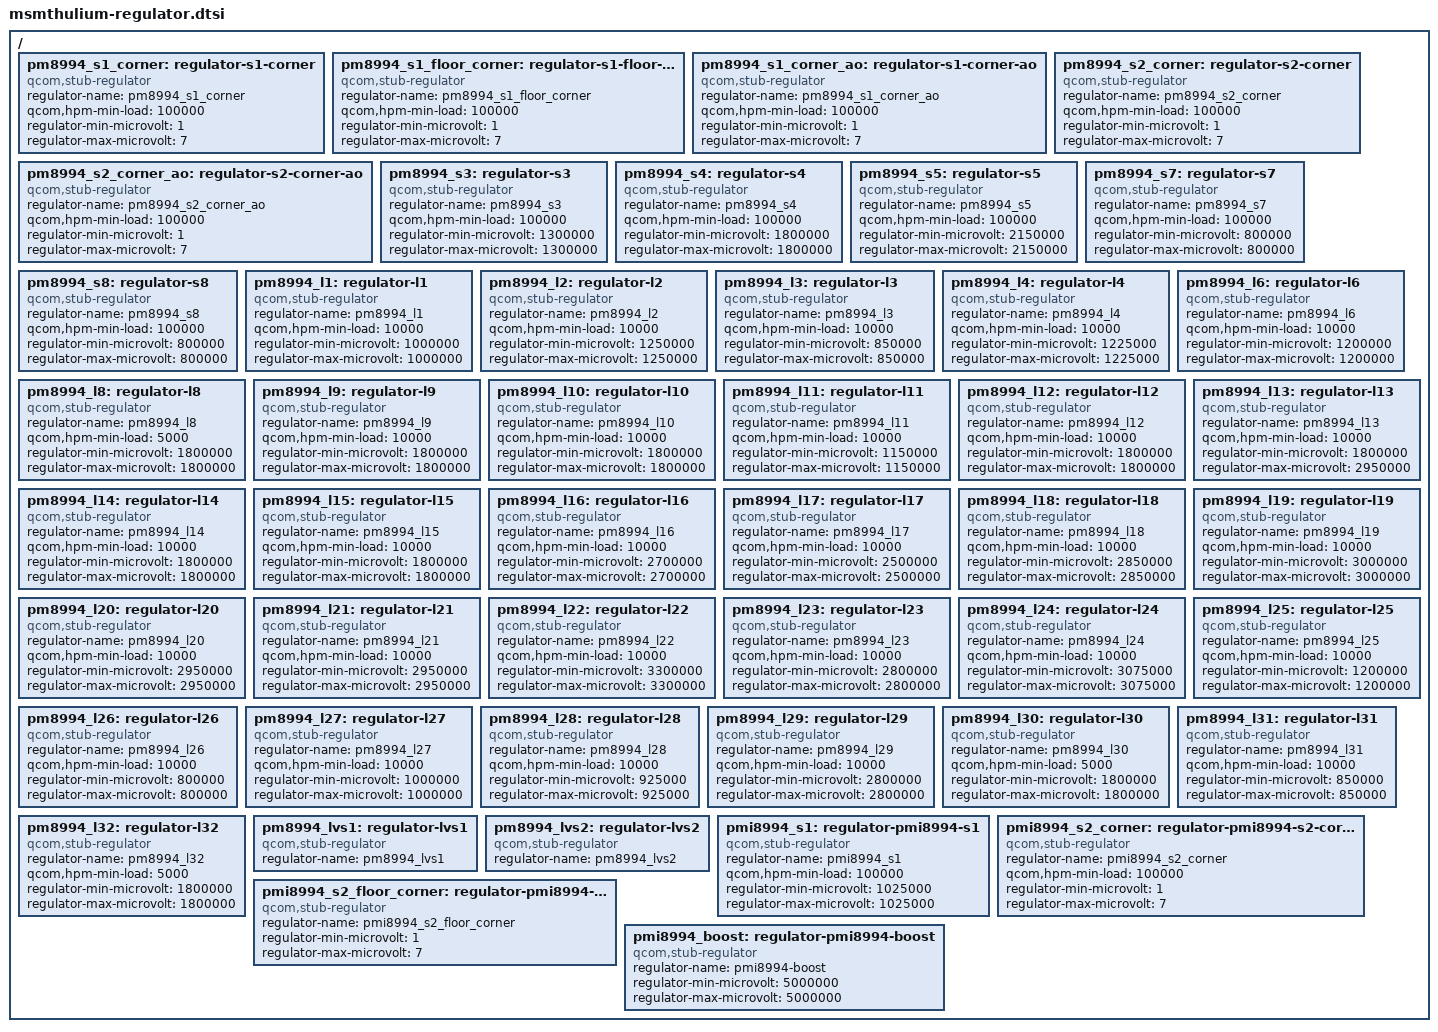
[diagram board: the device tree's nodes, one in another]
/* Copyright (c) 2014, The Linux Foundation. All rights reserved.
 *
 * This program is free software; you can redistribute it and/or modify
 * it under the terms of the GNU General Public License version 2 and
 * only version 2 as published by the Free Software Foundation.
 *
 * This program is distributed in the hope that it will be useful,
 * but WITHOUT ANY WARRANTY; without even the implied warranty of
 * MERCHANTABILITY or FITNESS FOR A PARTICULAR PURPOSE.  See the
 * GNU General Public License for more details.
 */

/* Stub regulators */

/ {
	/* PM8994 S1 + S6 = 2 phase VDD_CX supply */
	pm8994_s1_corner: regulator-s1-corner {
		compatible = "qcom,stub-regulator";
		regulator-name = "pm8994_s1_corner";
		qcom,hpm-min-load = <100000>;
		regulator-min-microvolt = <1>;
		regulator-max-microvolt = <7>;
	};

	pm8994_s1_floor_corner: regulator-s1-floor-corner {
		compatible = "qcom,stub-regulator";
		regulator-name = "pm8994_s1_floor_corner";
		qcom,hpm-min-load = <100000>;
		regulator-min-microvolt = <1>;
		regulator-max-microvolt = <7>;
	};

	pm8994_s1_corner_ao: regulator-s1-corner-ao {
		compatible = "qcom,stub-regulator";
		regulator-name = "pm8994_s1_corner_ao";
		qcom,hpm-min-load = <100000>;
		regulator-min-microvolt = <1>;
		regulator-max-microvolt = <7>;
	};

	/* PM8994 S2 + S12 = 2 phase VDD_MX supply */
	pm8994_s2_corner: regulator-s2-corner {
		compatible = "qcom,stub-regulator";
		regulator-name = "pm8994_s2_corner";
		qcom,hpm-min-load = <100000>;
		regulator-min-microvolt = <1>;
		regulator-max-microvolt = <7>;
	};

	pm8994_s2_corner_ao: regulator-s2-corner-ao {
		compatible = "qcom,stub-regulator";
		regulator-name = "pm8994_s2_corner_ao";
		qcom,hpm-min-load = <100000>;
		regulator-min-microvolt = <1>;
		regulator-max-microvolt = <7>;
	};

	pm8994_s3: regulator-s3 {
		compatible = "qcom,stub-regulator";
		regulator-name = "pm8994_s3";
		qcom,hpm-min-load = <100000>;
		regulator-min-microvolt = <1300000>;
		regulator-max-microvolt = <1300000>;
	};

	pm8994_s4: regulator-s4 {
		compatible = "qcom,stub-regulator";
		regulator-name = "pm8994_s4";
		qcom,hpm-min-load = <100000>;
		regulator-min-microvolt = <1800000>;
		regulator-max-microvolt = <1800000>;
	};

	pm8994_s5: regulator-s5 {
		compatible = "qcom,stub-regulator";
		regulator-name = "pm8994_s5";
		qcom,hpm-min-load = <100000>;
		regulator-min-microvolt = <2150000>;
		regulator-max-microvolt = <2150000>;
	};

	pm8994_s7: regulator-s7 {
		compatible = "qcom,stub-regulator";
		regulator-name = "pm8994_s7";
		qcom,hpm-min-load = <100000>;
		regulator-min-microvolt = <800000>;
		regulator-max-microvolt = <800000>;
	};

	/* PM8994 S8 + S9 + S10 + S11 = 4 phase VDD_APC supply */
	pm8994_s8: regulator-s8 {
		compatible = "qcom,stub-regulator";
		regulator-name = "pm8994_s8";
		qcom,hpm-min-load = <100000>;
		regulator-min-microvolt = <800000>;
		regulator-max-microvolt = <800000>;
	};

	pm8994_l1: regulator-l1 {
		compatible = "qcom,stub-regulator";
		regulator-name = "pm8994_l1";
		qcom,hpm-min-load = <10000>;
		regulator-min-microvolt = <1000000>;
		regulator-max-microvolt = <1000000>;
	};

	pm8994_l2: regulator-l2 {
		compatible = "qcom,stub-regulator";
		regulator-name = "pm8994_l2";
		qcom,hpm-min-load = <10000>;
		regulator-min-microvolt = <1250000>;
		regulator-max-microvolt = <1250000>;
	};

	pm8994_l3: regulator-l3 {
		compatible = "qcom,stub-regulator";
		regulator-name = "pm8994_l3";
		qcom,hpm-min-load = <10000>;
		regulator-min-microvolt = <850000>;
		regulator-max-microvolt = <850000>;
	};

	pm8994_l4: regulator-l4 {
		compatible = "qcom,stub-regulator";
		regulator-name = "pm8994_l4";
		qcom,hpm-min-load = <10000>;
		regulator-min-microvolt = <1225000>;
		regulator-max-microvolt = <1225000>;
	};

	pm8994_l6: regulator-l6 {
		compatible = "qcom,stub-regulator";
		regulator-name = "pm8994_l6";
		qcom,hpm-min-load = <10000>;
		regulator-min-microvolt = <1200000>;
		regulator-max-microvolt = <1200000>;
	};

	pm8994_l8: regulator-l8 {
		compatible = "qcom,stub-regulator";
		regulator-name = "pm8994_l8";
		qcom,hpm-min-load = <5000>;
		regulator-min-microvolt = <1800000>;
		regulator-max-microvolt = <1800000>;
	};

	pm8994_l9: regulator-l9 {
		compatible = "qcom,stub-regulator";
		regulator-name = "pm8994_l9";
		qcom,hpm-min-load = <10000>;
		regulator-min-microvolt = <1800000>;
		regulator-max-microvolt = <1800000>;
	};

	pm8994_l10: regulator-l10 {
		compatible = "qcom,stub-regulator";
		regulator-name = "pm8994_l10";
		qcom,hpm-min-load = <10000>;
		regulator-min-microvolt = <1800000>;
		regulator-max-microvolt = <1800000>;
	};

	pm8994_l11: regulator-l11 {
		compatible = "qcom,stub-regulator";
		regulator-name = "pm8994_l11";
		qcom,hpm-min-load = <10000>;
		regulator-min-microvolt = <1150000>;
		regulator-max-microvolt = <1150000>;
	};

	pm8994_l12: regulator-l12 {
		compatible = "qcom,stub-regulator";
		regulator-name = "pm8994_l12";
		qcom,hpm-min-load = <10000>;
		regulator-min-microvolt = <1800000>;
		regulator-max-microvolt = <1800000>;
	};

	pm8994_l13: regulator-l13 {
		compatible = "qcom,stub-regulator";
		regulator-name = "pm8994_l13";
		qcom,hpm-min-load = <10000>;
		regulator-min-microvolt = <1800000>;
		regulator-max-microvolt = <2950000>;
	};

	pm8994_l14: regulator-l14 {
		compatible = "qcom,stub-regulator";
		regulator-name = "pm8994_l14";
		qcom,hpm-min-load = <10000>;
		regulator-min-microvolt = <1800000>;
		regulator-max-microvolt = <1800000>;
	};

	pm8994_l15: regulator-l15 {
		compatible = "qcom,stub-regulator";
		regulator-name = "pm8994_l15";
		qcom,hpm-min-load = <10000>;
		regulator-min-microvolt = <1800000>;
		regulator-max-microvolt = <1800000>;
	};

	pm8994_l16: regulator-l16 {
		compatible = "qcom,stub-regulator";
		regulator-name = "pm8994_l16";
		qcom,hpm-min-load = <10000>;
		regulator-min-microvolt = <2700000>;
		regulator-max-microvolt = <2700000>;
	};

	pm8994_l17: regulator-l17 {
		compatible = "qcom,stub-regulator";
		regulator-name = "pm8994_l17";
		qcom,hpm-min-load = <10000>;
		regulator-min-microvolt = <2500000>;
		regulator-max-microvolt = <2500000>;
	};

	pm8994_l18: regulator-l18 {
		compatible = "qcom,stub-regulator";
		regulator-name = "pm8994_l18";
		qcom,hpm-min-load = <10000>;
		regulator-min-microvolt = <2850000>;
		regulator-max-microvolt = <2850000>;
	};

	pm8994_l19: regulator-l19 {
		compatible = "qcom,stub-regulator";
		regulator-name = "pm8994_l19";
		qcom,hpm-min-load = <10000>;
		regulator-min-microvolt = <3000000>;
		regulator-max-microvolt = <3000000>;
	};

	pm8994_l20: regulator-l20 {
		compatible = "qcom,stub-regulator";
		regulator-name = "pm8994_l20";
		qcom,hpm-min-load = <10000>;
		regulator-min-microvolt = <2950000>;
		regulator-max-microvolt = <2950000>;
	};

	pm8994_l21: regulator-l21 {
		compatible = "qcom,stub-regulator";
		regulator-name = "pm8994_l21";
		qcom,hpm-min-load = <10000>;
		regulator-min-microvolt = <2950000>;
		regulator-max-microvolt = <2950000>;
	};

	pm8994_l22: regulator-l22 {
		compatible = "qcom,stub-regulator";
		regulator-name = "pm8994_l22";
		qcom,hpm-min-load = <10000>;
		regulator-min-microvolt = <3300000>;
		regulator-max-microvolt = <3300000>;
	};

	pm8994_l23: regulator-l23 {
		compatible = "qcom,stub-regulator";
		regulator-name = "pm8994_l23";
		qcom,hpm-min-load = <10000>;
		regulator-min-microvolt = <2800000>;
		regulator-max-microvolt = <2800000>;
	};

	pm8994_l24: regulator-l24 {
		compatible = "qcom,stub-regulator";
		regulator-name = "pm8994_l24";
		qcom,hpm-min-load = <10000>;
		regulator-min-microvolt = <3075000>;
		regulator-max-microvolt = <3075000>;
	};

	pm8994_l25: regulator-l25 {
		compatible = "qcom,stub-regulator";
		regulator-name = "pm8994_l25";
		qcom,hpm-min-load = <10000>;
		regulator-min-microvolt = <1200000>;
		regulator-max-microvolt = <1200000>;
	};

	pm8994_l26: regulator-l26 {
		compatible = "qcom,stub-regulator";
		regulator-name = "pm8994_l26";
		qcom,hpm-min-load = <10000>;
		regulator-min-microvolt = <800000>;
		regulator-max-microvolt = <800000>;
	};

	pm8994_l27: regulator-l27 {
		compatible = "qcom,stub-regulator";
		regulator-name = "pm8994_l27";
		qcom,hpm-min-load = <10000>;
		regulator-min-microvolt = <1000000>;
		regulator-max-microvolt = <1000000>;
	};

	pm8994_l28: regulator-l28 {
		compatible = "qcom,stub-regulator";
		regulator-name = "pm8994_l28";
		qcom,hpm-min-load = <10000>;
		regulator-min-microvolt = <925000>;
		regulator-max-microvolt = <925000>;
	};

	pm8994_l29: regulator-l29 {
		compatible = "qcom,stub-regulator";
		regulator-name = "pm8994_l29";
		qcom,hpm-min-load = <10000>;
		regulator-min-microvolt = <2800000>;
		regulator-max-microvolt = <2800000>;
	};

	pm8994_l30: regulator-l30 {
		compatible = "qcom,stub-regulator";
		regulator-name = "pm8994_l30";
		qcom,hpm-min-load = <5000>;
		regulator-min-microvolt = <1800000>;
		regulator-max-microvolt = <1800000>;
	};

	pm8994_l31: regulator-l31 {
		compatible = "qcom,stub-regulator";
		regulator-name = "pm8994_l31";
		qcom,hpm-min-load = <10000>;
		regulator-min-microvolt = <850000>;
		regulator-max-microvolt = <850000>;
	};

	pm8994_l32: regulator-l32 {
		compatible = "qcom,stub-regulator";
		regulator-name = "pm8994_l32";
		qcom,hpm-min-load = <5000>;
		regulator-min-microvolt = <1800000>;
		regulator-max-microvolt = <1800000>;
	};

	pm8994_lvs1: regulator-lvs1 {
		compatible = "qcom,stub-regulator";
		regulator-name = "pm8994_lvs1";
	};

	pm8994_lvs2: regulator-lvs2 {
		compatible = "qcom,stub-regulator";
		regulator-name = "pm8994_lvs2";
	};

	pmi8994_s1: regulator-pmi8994-s1{
		compatible = "qcom,stub-regulator";
		regulator-name = "pmi8994_s1";
		qcom,hpm-min-load = <100000>;
		regulator-min-microvolt = <1025000>;
		regulator-max-microvolt = <1025000>;
	};

	/* PMI8994 S2 + S3 = 2 phase VDD_GFX supply */
	pmi8994_s2_corner: regulator-pmi8994-s2-corner {
		compatible = "qcom,stub-regulator";
		regulator-name = "pmi8994_s2_corner";
		qcom,hpm-min-load = <100000>;
		regulator-min-microvolt = <1>;
		regulator-max-microvolt = <7>;
	};

	pmi8994_s2_floor_corner: regulator-pmi8994-s2-floor-corner {
		compatible = "qcom,stub-regulator";
		regulator-name = "pmi8994_s2_floor_corner";
		regulator-min-microvolt = <1>;
		regulator-max-microvolt = <7>;
	};

	pmi8994_boost: regulator-pmi8994-boost {
		compatible = "qcom,stub-regulator";
		regulator-name = "pmi8994-boost";
		regulator-min-microvolt = <5000000>;
		regulator-max-microvolt = <5000000>;
	};
};
